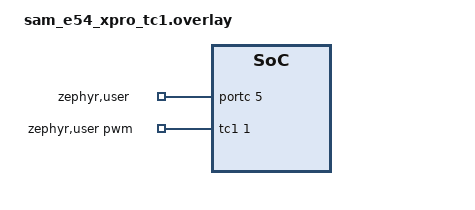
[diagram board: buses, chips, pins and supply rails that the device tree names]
/*
 * Copyright (c) 2025-2026 Microchip Technology Inc.
 * SPDX-License-Identifier: Apache-2.0
 */

/* connect PA07 to PC05 */

#define PWM_NODE     tc1
#define PWM_PINCTRL  tc1_pwm_default
#include "mchp_pwm_loopback_support.dtsi"

/ {
	zephyr,user {
		pwms = <&tc1 1 PWM_MSEC(1) 0>;
		gpios = <&portc 5 GPIO_ACTIVE_HIGH>;
	};
};

&portc {
	status = "okay";
};

&pinctrl {
	tc1_pwm_default: tc1_pwm_default {
		group1 {
			pinmux = <PA7E_TC1_WO1>;
		};
	};
};
